VERSION ""

NS_ :

BS_:

BU_:
VAL_TABLE_ DPadSt 13 "NA" 12 "Error" 11 "Btn5Hld" 10 "Btn4Hld" 9 "Btn3Hld" 8 "Btn2Hld" 7 "Btn1Hld2" 6 "Btn1Hld" 5 "Btn5Psd" 4 "Btn4Psd" 3 "Btn3Psd" 2 "Btn2Psd" 1 "Btn1Psd" 0 "NoAction" ;

BO_ 3221225472 VECTOR__INDEPENDENT_SIG_MSG: 0 Vector__XXX
 SG_ LeDPadSt : 0|4@1+ (1,0) [0|15] "" Vector__XXX

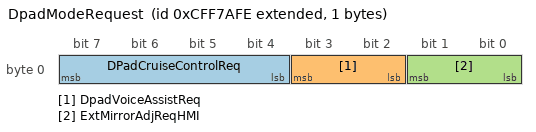
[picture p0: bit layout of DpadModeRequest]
BO_ 2365553406 DpadModeRequest: 1 Vector__XXX
 SG_ DPadCruiseControlReq : 4|4@1+ (1,0) [0|15] "" Vector__XXX
 SG_ DpadVoiceAssistReq : 2|2@1+ (1,0) [0|3] "" Vector__XXX
 SG_ ExtMirrorAdjReqHMI : 0|2@1+ (1,0) [0|3] "" Vector__XXX

BO_ 2381855998 RightDPadState: 1 Vector__XXX
 SG_ RiDPadSt : 0|4@1+ (1,0) [0|15] "" Vector__XXX

BO_ 2381855742 LeftDPadState: 1 Vector__XXX
 SG_ LeDPadSt : 0|4@1+ (1,0) [0|15] "" Vector__XXX

CM_ "$File: //depot/auto/dbc/Software_Modules/DPad/0.1.6.0/DPad.dbc $
$Change: 215973 $
$DateTime: 2024/08/21 10:03:26 $
$Revision: #1 $";
CM_ BO_ 3221225472 "This is a message for not used signals, created by Vector CANdb++ DBC OLE DB Provider.";
CM_ SG_ 2365553406 DPadCruiseControlReq "Status of Mirror Adjastment mode request from HMI(Requested /not requested)";
CM_ SG_ 2365553406 DpadVoiceAssistReq "Status of Mirror Adjastment mode request from HMI(Requested /not requested)";
CM_ SG_ 2365553406 ExtMirrorAdjReqHMI "Status of Mirror Adjastment mode request from HMI(Requested /not requested)";
BA_DEF_ BO_  "SendOnChange" ENUM  "No","Yes";
BA_DEF_ SG_  "SigType" ENUM  "Default","Range","RangeSigned","ASCII","Discrete","Control","ReferencePGN","DTC","StringDelimiter","StringLength","StringLengthControl","MessageCounter","MessageChecksum";
BA_DEF_ SG_  "GenSigEVName" STRING ;
BA_DEF_ SG_  "GenSigILSupport" ENUM  "No","Yes";
BA_DEF_ SG_  "GenSigSendType" ENUM  "Cyclic","OnWrite","OnWriteWithRepetition","OnChange","OnChangeWithRepetition","IfActive","IfActiveWithRepetition","NoSigSendType";
BA_DEF_ SG_  "GenSigStartValue" INT 0 2147483647;
BA_DEF_ BO_  "GenMsgDelayTime" INT 0 1000;
BA_DEF_ BO_  "GenMsgILSupport" ENUM  "No","Yes";
BA_DEF_ BU_  "NmStationAddress" INT 0 255;
BA_DEF_ BO_  "GenMsgSendType" ENUM  "cyclic","NotUsed","IfActive","NotUsed","NotUsed","NotUsed","NotUsed","NotUsed","noMsgSendType";
BA_DEF_ BO_  "GenMsgRequestable" INT 0 1;
BA_DEF_ BO_  "GenMsgCycleTime" INT 0 3600000;
BA_DEF_  "DBName" STRING ;
BA_DEF_  "BusType" STRING ;
BA_DEF_  "ProtocolType" STRING ;
BA_DEF_ BO_  "VFrameFormat" ENUM  "StandardCAN","ExtendedCAN","reserved","J1939PG";
BA_DEF_ BO_  "Producer" STRING ;
BA_DEF_DEF_  "SendOnChange" "No";
BA_DEF_DEF_  "SigType" "Default";
BA_DEF_DEF_  "GenSigEVName" "Env@Nodename_@Signame";
BA_DEF_DEF_  "GenSigILSupport" "Yes";
BA_DEF_DEF_  "GenSigSendType" "NoSigSendType";
BA_DEF_DEF_  "GenSigStartValue" 0;
BA_DEF_DEF_  "GenMsgDelayTime" 0;
BA_DEF_DEF_  "GenMsgILSupport" "Yes";
BA_DEF_DEF_  "NmStationAddress" 254;
BA_DEF_DEF_  "GenMsgSendType" "noMsgSendType";
BA_DEF_DEF_  "GenMsgRequestable" 1;
BA_DEF_DEF_  "GenMsgCycleTime" 0;
BA_DEF_DEF_  "DBName" "";
BA_DEF_DEF_  "BusType" "CAN";
BA_DEF_DEF_  "ProtocolType" "J1939";
BA_DEF_DEF_  "VFrameFormat" "J1939PG";
BA_ "DBName" "DPad";
BA_ "GenMsgDelayTime" BO_ 2365553406 100;
BA_ "SendOnChange" BO_ 2365553406 1;
BA_ "GenMsgCycleTime" BO_ 2365553406 1000;
BA_ "GenMsgSendType" BO_ 2365553406 0;
BA_ "GenMsgDelayTime" BO_ 2381855998 100;
BA_ "GenMsgCycleTime" BO_ 2381855998 1000;
BA_ "SendOnChange" BO_ 2381855998 1;
BA_ "GenMsgDelayTime" BO_ 2381855742 100;
BA_ "GenMsgCycleTime" BO_ 2381855742 1000;
BA_ "SendOnChange" BO_ 2381855742 1;
BA_ "GenSigStartValue" SG_ 2365553406 DPadCruiseControlReq 3;
BA_ "GenSigStartValue" SG_ 2365553406 DpadVoiceAssistReq 3;
BA_ "GenSigStartValue" SG_ 2365553406 ExtMirrorAdjReqHMI 3;
BA_ "Producer" BO_ 2381855742 "UICS";
BA_ "Producer" BO_ 2381855998 "UICS";
VAL_ 3221225472 LeDPadSt 15 "NA" 14 "Error" 13 "Reserved" 12 "Btn5Hld3" 11 "Btn5Hld" 10 "Btn4Hld" 9 "Btn3Hld" 8 "Btn2Hld" 7 "Btn1Hld2" 6 "Btn1Hld" 5 "Btn5Psd" 4 "Btn4Psd" 3 "Btn3Psd" 2 "Btn2Psd" 1 "Btn1Psd" 0 "NoAction" ;
VAL_ 2365553406 DPadCruiseControlReq 8 "SetSpeed" 7 "ModeChange" 6 "SlowDownMajor" 5 "SlowDownMinor" 4 "SpeedUpMajor" 3 "SpeedUpMinor" 2 "RequestOff" 1 "RequestOn" 0 "NoAction" ;
VAL_ 2365553406 DpadVoiceAssistReq 3 "NA" 2 "Error" 1 "On" 0 "Off" ;
VAL_ 2365553406 ExtMirrorAdjReqHMI 3 "NA" 2 "Error" 1 "On" 0 "Off" ;
VAL_ 2381855998 RiDPadSt 15 "NA" 14 "Error" 13 "Reserved" 12 "Btn5Hld3" 11 "Btn5Hld" 10 "Btn4Hld" 9 "Btn3Hld" 8 "Btn2Hld" 7 "Btn1Hld2" 6 "Btn1Hld" 5 "Btn5Psd" 4 "Btn4Psd" 3 "Btn3Psd" 2 "Btn2Psd" 1 "Btn1Psd" 0 "NoAction" ;
VAL_ 2381855742 LeDPadSt 15 "NA" 14 "Error" 13 "Reserved" 12 "Btn5Hld3" 11 "Btn5Hld" 10 "Btn4Hld" 9 "Btn3Hld" 8 "Btn2Hld" 7 "Btn1Hld2" 6 "Btn1Hld" 5 "Btn5Psd" 4 "Btn4Psd" 3 "Btn3Psd" 2 "Btn2Psd" 1 "Btn1Psd" 0 "NoAction" ;
